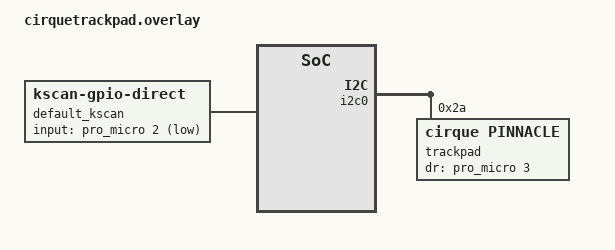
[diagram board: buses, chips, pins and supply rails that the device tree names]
// cirquetrackpad.overlay

/ {
    chosen {
        zmk,kscan = &default_kscan;
    };

    default_kscan: kscan {
        compatible = "zmk,kscan-gpio-direct";
        //label = "default_kscan";
        //diode-direction = "col2row";

        input-gpios
            = <&pro_micro 2 (GPIO_ACTIVE_LOW | GPIO_PULL_UP)> // Row A from the schematic file
            //, <&pro_micro 1 (GPIO_ACTIVE_LOW | GPIO_PULL_UP)> // Row B from the schematic file
            //, <&pro_micro 0 (GPIO_ACTIVE_LOW | GPIO_PULL_UP)> // Row C from the schematic file
            ;
    };
};

&i2c0  {
    status = "okay";
    trackpad@2a {
	    compatible = "cirque,pinnacle";
	    reg = <0x2a>;
	    //label = "Cirque_Trackpad";
        dr-gpios = <&pro_micro	3	GPIO_ACTIVE_HIGH>;
	    rotate-90;
	    //sleep;
	    //no-taps;
    };
};
